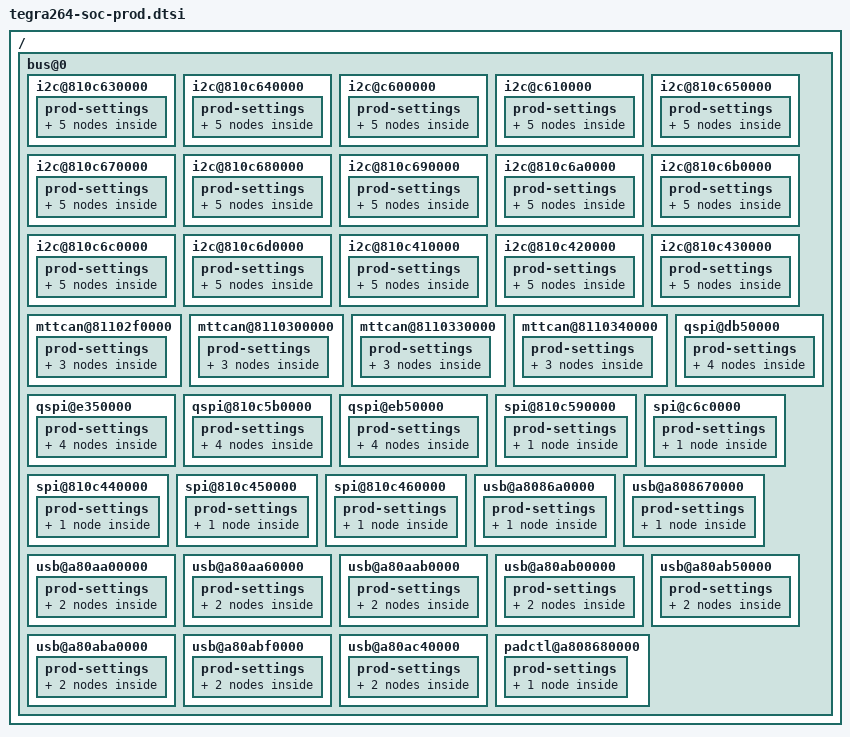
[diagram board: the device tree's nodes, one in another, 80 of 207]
/*
* tegra264-soc-prod.dtsi: soc specific Prod configuration.
* Generation date: 2025-03-05 16:42
* PLEASE DO NOT EDIT THIS FILE MANUALLY
* This file is autogenerated using the script gen_prod_dtsi.py V2.4 in $TOP/tools/golden-regs/host_tools_python3/auto_gen_tools 
* NOTE: Do not use file as is. Copy the relevant section to existing                 file in tree.
* NOTE: FIXME nodes indicate nodes corresponding to Golden Register                 were not found in input DTB.
*       Please check if DTB has the nodes enabled and register address                 in GR DB is valid.
*/

/ {


	bus@0{
		i2c@810c630000 { /* I2C0 */
			prod-settings {
				#prod-cells = <4>;
				prod {
					prod = <

						0 0x000000d4 0x000000ff 0x00000000              //I2C_I2C_INTERFACE_TIMING_2_0
						0 0x000000d8 0x000000ff 0x00000000              //I2C_I2C_HS_INTERFACE_TIMING_2_0
						0 0x000000dc 0x0000ffff 0x00000001              //I2C_I2C_MSTR_DATA_CAPTURE_TIMING_0
						0 0x000000e0 0x0000ffff 0x00000002>;            //I2C_I2C_SLV_DATA_CAPTURE_TIMING_0
				};
				prod_c_fm {
					prod = <
						0 0x0000006c 0xffff0000 0x00150000              //I2C_I2C_CLK_DIVISOR_REGISTER_0
						0 0x00000094 0x0000ffff 0x00000202              //I2C_I2C_INTERFACE_TIMING_0_0
						0 0x00000098 0xffffffff 0x02020202              //I2C_I2C_INTERFACE_TIMING_1_0
						0 0x000000e8 0x000000ff 0x00000040>;            //I2C_I2C_FAIRNESS_ARBITRATION_0
				};
				prod_c_fmplus {
					prod = <
						0 0x0000006c 0xffff0000 0x00080000              //I2C_I2C_CLK_DIVISOR_REGISTER_0
						0 0x00000094 0x0000ffff 0x00000202              //I2C_I2C_INTERFACE_TIMING_0_0
						0 0x00000098 0xffffffff 0x02020202              //I2C_I2C_INTERFACE_TIMING_1_0
						0 0x000000e8 0x000000ff 0x00000040>;            //I2C_I2C_FAIRNESS_ARBITRATION_0
				};
				prod_c_hs {
					prod = <
						0 0x0000006c 0xffffffff 0x001d0002              //I2C_I2C_CLK_DIVISOR_REGISTER_0
						0 0x00000094 0x0000ffff 0x00000202              //I2C_I2C_INTERFACE_TIMING_0_0
						0 0x00000098 0xffffffff 0x02020202              //I2C_I2C_INTERFACE_TIMING_1_0
						0 0x0000009c 0x0000ffff 0x00000102              //I2C_I2C_HS_INTERFACE_TIMING_0_0
						0 0x000000a0 0x00ffffff 0x00040404              //I2C_I2C_HS_INTERFACE_TIMING_1_0
						0 0x000000e8 0x000000ff 0x00000040>;            //I2C_I2C_FAIRNESS_ARBITRATION_0
				};
				prod_c_sm {
					prod = <
						0 0x0000006c 0xffff0000 0x001d0000              //I2C_I2C_CLK_DIVISOR_REGISTER_0
						0 0x00000094 0x0000ffff 0x00000708              //I2C_I2C_INTERFACE_TIMING_0_0
						0 0x00000098 0xffffffff 0x08080808              //I2C_I2C_INTERFACE_TIMING_1_0
						0 0x000000e8 0x000000ff 0x00000040>;            //I2C_I2C_FAIRNESS_ARBITRATION_0
				};
			};
		};

		i2c@810c640000 { /* I2C1 */
			prod-settings {
				#prod-cells = <4>;
				prod {
					prod = <

						0 0x000000d4 0x000000ff 0x00000000              //I2C_I2C_INTERFACE_TIMING_2_0
						0 0x000000d8 0x000000ff 0x00000000              //I2C_I2C_HS_INTERFACE_TIMING_2_0
						0 0x000000dc 0x0000ffff 0x00000001              //I2C_I2C_MSTR_DATA_CAPTURE_TIMING_0
						0 0x000000e0 0x0000ffff 0x00000002>;            //I2C_I2C_SLV_DATA_CAPTURE_TIMING_0
				};
				prod_c_fm {
					prod = <
						0 0x0000006c 0xffff0000 0x00150000              //I2C_I2C_CLK_DIVISOR_REGISTER_0
						0 0x00000094 0x0000ffff 0x00000202              //I2C_I2C_INTERFACE_TIMING_0_0
						0 0x00000098 0xffffffff 0x02020202              //I2C_I2C_INTERFACE_TIMING_1_0
						0 0x000000e8 0x000000ff 0x00000040>;            //I2C_I2C_FAIRNESS_ARBITRATION_0
				};
				prod_c_fmplus {
					prod = <
						0 0x0000006c 0xffff0000 0x00080000              //I2C_I2C_CLK_DIVISOR_REGISTER_0
						0 0x00000094 0x0000ffff 0x00000202              //I2C_I2C_INTERFACE_TIMING_0_0
						0 0x00000098 0xffffffff 0x02020202              //I2C_I2C_INTERFACE_TIMING_1_0
						0 0x000000e8 0x000000ff 0x00000040>;            //I2C_I2C_FAIRNESS_ARBITRATION_0
				};
				prod_c_hs {
					prod = <
						0 0x0000006c 0xffffffff 0x001d0002              //I2C_I2C_CLK_DIVISOR_REGISTER_0
						0 0x00000094 0x0000ffff 0x00000202              //I2C_I2C_INTERFACE_TIMING_0_0
						0 0x00000098 0xffffffff 0x02020202              //I2C_I2C_INTERFACE_TIMING_1_0
						0 0x0000009c 0x0000ffff 0x00000102              //I2C_I2C_HS_INTERFACE_TIMING_0_0
						0 0x000000a0 0x00ffffff 0x00040404              //I2C_I2C_HS_INTERFACE_TIMING_1_0
						0 0x000000e8 0x000000ff 0x00000040>;            //I2C_I2C_FAIRNESS_ARBITRATION_0
				};
				prod_c_sm {
					prod = <
						0 0x0000006c 0xffff0000 0x001d0000              //I2C_I2C_CLK_DIVISOR_REGISTER_0
						0 0x00000094 0x0000ffff 0x00000708              //I2C_I2C_INTERFACE_TIMING_0_0
						0 0x00000098 0xffffffff 0x08080808              //I2C_I2C_INTERFACE_TIMING_1_0
						0 0x000000e8 0x000000ff 0x00000040>;            //I2C_I2C_FAIRNESS_ARBITRATION_0
				};
			};
		};

		i2c@c600000 { /* I2C2 */
			prod-settings {
				#prod-cells = <4>;
				prod {
					prod = <

						0 0x000000d4 0x000000ff 0x00000000              //I2C_I2C_INTERFACE_TIMING_2_0
						0 0x000000d8 0x000000ff 0x00000000              //I2C_I2C_HS_INTERFACE_TIMING_2_0
						0 0x000000dc 0x0000ffff 0x00000001              //I2C_I2C_MSTR_DATA_CAPTURE_TIMING_0
						0 0x000000e0 0x0000ffff 0x00000002>;            //I2C_I2C_SLV_DATA_CAPTURE_TIMING_0
				};
				prod_c_fm {
					prod = <
						0 0x0000006c 0xffff0000 0x00180000              //I2C_I2C_CLK_DIVISOR_REGISTER_0
						0 0x00000094 0x0000ffff 0x00000202              //I2C_I2C_INTERFACE_TIMING_0_0
						0 0x00000098 0xffffffff 0x02020202              //I2C_I2C_INTERFACE_TIMING_1_0
						0 0x000000e8 0x000000ff 0x00000040>;            //I2C_I2C_FAIRNESS_ARBITRATION_0
				};
				prod_c_fmplus {
					prod = <
						0 0x0000006c 0xffff0000 0x00090000              //I2C_I2C_CLK_DIVISOR_REGISTER_0
						0 0x00000094 0x0000ffff 0x00000202              //I2C_I2C_INTERFACE_TIMING_0_0
						0 0x00000098 0xffffffff 0x02020202              //I2C_I2C_INTERFACE_TIMING_1_0
						0 0x000000e8 0x000000ff 0x00000040>;            //I2C_I2C_FAIRNESS_ARBITRATION_0
				};
				prod_c_hs {
					prod = <
						0 0x0000006c 0xffffffff 0x00180002              //I2C_I2C_CLK_DIVISOR_REGISTER_0
						0 0x00000094 0x0000ffff 0x00000202              //I2C_I2C_INTERFACE_TIMING_0_0
						0 0x00000098 0xffffffff 0x02020202              //I2C_I2C_INTERFACE_TIMING_1_0
						0 0x000000a0 0x00ffffff 0x00090909              //I2C_I2C_HS_INTERFACE_TIMING_1_0
						0 0x000000e8 0x000000ff 0x00000040>;            //I2C_I2C_FAIRNESS_ARBITRATION_0
				};
				prod_c_sm {
					prod = <
						0 0x0000006c 0xffff0000 0x00230000              //I2C_I2C_CLK_DIVISOR_REGISTER_0
						0 0x00000094 0x0000ffff 0x00000708              //I2C_I2C_INTERFACE_TIMING_0_0
						0 0x00000098 0xffffffff 0x08080808              //I2C_I2C_INTERFACE_TIMING_1_0
						0 0x000000e8 0x000000ff 0x00000040>;            //I2C_I2C_FAIRNESS_ARBITRATION_0
				};
			};
		};

		i2c@c610000 { /* I2C3 */
			prod-settings {
				#prod-cells = <4>;
				prod {
					prod = <

						0 0x000000d4 0x000000ff 0x00000000              //I2C_I2C_INTERFACE_TIMING_2_0
						0 0x000000d8 0x000000ff 0x00000000              //I2C_I2C_HS_INTERFACE_TIMING_2_0
						0 0x000000dc 0x0000ffff 0x00000001              //I2C_I2C_MSTR_DATA_CAPTURE_TIMING_0
						0 0x000000e0 0x0000ffff 0x00000002>;            //I2C_I2C_SLV_DATA_CAPTURE_TIMING_0
				};
				prod_c_fm {
					prod = <
						0 0x0000006c 0xffff0000 0x00180000              //I2C_I2C_CLK_DIVISOR_REGISTER_0
						0 0x00000094 0x0000ffff 0x00000202              //I2C_I2C_INTERFACE_TIMING_0_0
						0 0x00000098 0xffffffff 0x02020202              //I2C_I2C_INTERFACE_TIMING_1_0
						0 0x000000e8 0x000000ff 0x00000040>;            //I2C_I2C_FAIRNESS_ARBITRATION_0
				};
				prod_c_fmplus {
					prod = <
						0 0x0000006c 0xffff0000 0x00090000              //I2C_I2C_CLK_DIVISOR_REGISTER_0
						0 0x00000094 0x0000ffff 0x00000202              //I2C_I2C_INTERFACE_TIMING_0_0
						0 0x00000098 0xffffffff 0x02020202              //I2C_I2C_INTERFACE_TIMING_1_0
						0 0x000000e8 0x000000ff 0x00000040>;            //I2C_I2C_FAIRNESS_ARBITRATION_0
				};
				prod_c_hs {
					prod = <
						0 0x0000006c 0xffffffff 0x00180002              //I2C_I2C_CLK_DIVISOR_REGISTER_0
						0 0x00000094 0x0000ffff 0x00000202              //I2C_I2C_INTERFACE_TIMING_0_0
						0 0x00000098 0xffffffff 0x02020202              //I2C_I2C_INTERFACE_TIMING_1_0
						0 0x000000a0 0x00ffffff 0x00090909              //I2C_I2C_HS_INTERFACE_TIMING_1_0
						0 0x000000e8 0x000000ff 0x00000040>;            //I2C_I2C_FAIRNESS_ARBITRATION_0
				};
				prod_c_sm {
					prod = <
						0 0x0000006c 0xffff0000 0x00230000              //I2C_I2C_CLK_DIVISOR_REGISTER_0
						0 0x00000094 0x0000ffff 0x00000708              //I2C_I2C_INTERFACE_TIMING_0_0
						0 0x00000098 0xffffffff 0x08080808              //I2C_I2C_INTERFACE_TIMING_1_0
						0 0x000000e8 0x000000ff 0x00000040>;            //I2C_I2C_FAIRNESS_ARBITRATION_0
				};
			};
		};

		i2c@810c650000 { /* I2C4 */
			prod-settings {
				#prod-cells = <4>;
				prod {
					prod = <

						0 0x000000d4 0x000000ff 0x00000000              //I2C_I2C_INTERFACE_TIMING_2_0
						0 0x000000d8 0x000000ff 0x00000000              //I2C_I2C_HS_INTERFACE_TIMING_2_0
						0 0x000000dc 0x0000ffff 0x00000001              //I2C_I2C_MSTR_DATA_CAPTURE_TIMING_0
						0 0x000000e0 0x0000ffff 0x00000002>;            //I2C_I2C_SLV_DATA_CAPTURE_TIMING_0
				};
				prod_c_fm {
					prod = <
						0 0x0000006c 0xffff0000 0x00150000              //I2C_I2C_CLK_DIVISOR_REGISTER_0
						0 0x00000094 0x0000ffff 0x00000202              //I2C_I2C_INTERFACE_TIMING_0_0
						0 0x00000098 0xffffffff 0x02020202              //I2C_I2C_INTERFACE_TIMING_1_0
						0 0x000000e8 0x000000ff 0x00000040>;            //I2C_I2C_FAIRNESS_ARBITRATION_0
				};
				prod_c_fmplus {
					prod = <
						0 0x0000006c 0xffff0000 0x00080000              //I2C_I2C_CLK_DIVISOR_REGISTER_0
						0 0x00000094 0x0000ffff 0x00000202              //I2C_I2C_INTERFACE_TIMING_0_0
						0 0x00000098 0xffffffff 0x02020202              //I2C_I2C_INTERFACE_TIMING_1_0
						0 0x000000e8 0x000000ff 0x00000040>;            //I2C_I2C_FAIRNESS_ARBITRATION_0
				};
				prod_c_hs {
					prod = <
						0 0x0000006c 0xffffffff 0x001d0002              //I2C_I2C_CLK_DIVISOR_REGISTER_0
						0 0x00000094 0x0000ffff 0x00000202              //I2C_I2C_INTERFACE_TIMING_0_0
						0 0x00000098 0xffffffff 0x02020202              //I2C_I2C_INTERFACE_TIMING_1_0
						0 0x0000009c 0x0000ffff 0x00000102              //I2C_I2C_HS_INTERFACE_TIMING_0_0
						0 0x000000a0 0x00ffffff 0x00040404              //I2C_I2C_HS_INTERFACE_TIMING_1_0
						0 0x000000e8 0x000000ff 0x00000040>;            //I2C_I2C_FAIRNESS_ARBITRATION_0
				};
				prod_c_sm {
					prod = <
						0 0x0000006c 0xffff0000 0x001d0000              //I2C_I2C_CLK_DIVISOR_REGISTER_0
						0 0x00000094 0x0000ffff 0x00000708              //I2C_I2C_INTERFACE_TIMING_0_0
						0 0x00000098 0xffffffff 0x08080808              //I2C_I2C_INTERFACE_TIMING_1_0
						0 0x000000e8 0x000000ff 0x00000040>;            //I2C_I2C_FAIRNESS_ARBITRATION_0
				};
			};
		};



		i2c@810c670000 { /* I2C6 */
			prod-settings {
				#prod-cells = <4>;
				prod {
					prod = <

						0 0x000000d4 0x000000ff 0x00000000              //I2C_I2C_INTERFACE_TIMING_2_0
						0 0x000000d8 0x000000ff 0x00000000              //I2C_I2C_HS_INTERFACE_TIMING_2_0
						0 0x000000dc 0x0000ffff 0x00000001              //I2C_I2C_MSTR_DATA_CAPTURE_TIMING_0
						0 0x000000e0 0x0000ffff 0x00000002>;            //I2C_I2C_SLV_DATA_CAPTURE_TIMING_0
				};
				prod_c_fm {
					prod = <
						0 0x0000006c 0xffff0000 0x00150000              //I2C_I2C_CLK_DIVISOR_REGISTER_0
						0 0x00000094 0x0000ffff 0x00000202              //I2C_I2C_INTERFACE_TIMING_0_0
						0 0x00000098 0xffffffff 0x02020202              //I2C_I2C_INTERFACE_TIMING_1_0
						0 0x000000e8 0x000000ff 0x00000040>;            //I2C_I2C_FAIRNESS_ARBITRATION_0
				};
				prod_c_fmplus {
					prod = <
						0 0x0000006c 0xffff0000 0x00080000              //I2C_I2C_CLK_DIVISOR_REGISTER_0
						0 0x00000094 0x0000ffff 0x00000202              //I2C_I2C_INTERFACE_TIMING_0_0
						0 0x00000098 0xffffffff 0x02020202              //I2C_I2C_INTERFACE_TIMING_1_0
						0 0x000000e8 0x000000ff 0x00000040>;            //I2C_I2C_FAIRNESS_ARBITRATION_0
				};
				prod_c_hs {
					prod = <
						0 0x0000006c 0xffffffff 0x001d0002              //I2C_I2C_CLK_DIVISOR_REGISTER_0
						0 0x00000094 0x0000ffff 0x00000202              //I2C_I2C_INTERFACE_TIMING_0_0
						0 0x00000098 0xffffffff 0x02020202              //I2C_I2C_INTERFACE_TIMING_1_0
						0 0x0000009c 0x0000ffff 0x00000102              //I2C_I2C_HS_INTERFACE_TIMING_0_0
						0 0x000000a0 0x00ffffff 0x00040404              //I2C_I2C_HS_INTERFACE_TIMING_1_0
						0 0x000000e8 0x000000ff 0x00000040>;            //I2C_I2C_FAIRNESS_ARBITRATION_0
				};
				prod_c_sm {
					prod = <
						0 0x0000006c 0xffff0000 0x001d0000              //I2C_I2C_CLK_DIVISOR_REGISTER_0
						0 0x00000094 0x0000ffff 0x00000708              //I2C_I2C_INTERFACE_TIMING_0_0
						0 0x00000098 0xffffffff 0x08080808              //I2C_I2C_INTERFACE_TIMING_1_0
						0 0x000000e8 0x000000ff 0x00000040>;            //I2C_I2C_FAIRNESS_ARBITRATION_0
				};
			};
		};

		i2c@810c680000 { /* I2C7 */
			prod-settings {
				#prod-cells = <4>;
				prod {
					prod = <

						0 0x000000d4 0x000000ff 0x00000000              //I2C_I2C_INTERFACE_TIMING_2_0
						0 0x000000d8 0x000000ff 0x00000000              //I2C_I2C_HS_INTERFACE_TIMING_2_0
						0 0x000000dc 0x0000ffff 0x00000001              //I2C_I2C_MSTR_DATA_CAPTURE_TIMING_0
						0 0x000000e0 0x0000ffff 0x00000002>;            //I2C_I2C_SLV_DATA_CAPTURE_TIMING_0
				};
				prod_c_fm {
					prod = <
						0 0x0000006c 0xffff0000 0x00150000              //I2C_I2C_CLK_DIVISOR_REGISTER_0
						0 0x00000094 0x0000ffff 0x00000202              //I2C_I2C_INTERFACE_TIMING_0_0
						0 0x00000098 0xffffffff 0x02020202              //I2C_I2C_INTERFACE_TIMING_1_0
						0 0x000000e8 0x000000ff 0x00000040>;            //I2C_I2C_FAIRNESS_ARBITRATION_0
				};
				prod_c_fmplus {
					prod = <
						0 0x0000006c 0xffff0000 0x00080000              //I2C_I2C_CLK_DIVISOR_REGISTER_0
						0 0x00000094 0x0000ffff 0x00000202              //I2C_I2C_INTERFACE_TIMING_0_0
						0 0x00000098 0xffffffff 0x02020202              //I2C_I2C_INTERFACE_TIMING_1_0
						0 0x000000e8 0x000000ff 0x00000040>;            //I2C_I2C_FAIRNESS_ARBITRATION_0
				};
				prod_c_hs {
					prod = <
						0 0x0000006c 0xffffffff 0x001d0002              //I2C_I2C_CLK_DIVISOR_REGISTER_0
						0 0x00000094 0x0000ffff 0x00000202              //I2C_I2C_INTERFACE_TIMING_0_0
						0 0x00000098 0xffffffff 0x02020202              //I2C_I2C_INTERFACE_TIMING_1_0
						0 0x0000009c 0x0000ffff 0x00000102              //I2C_I2C_HS_INTERFACE_TIMING_0_0
						0 0x000000a0 0x00ffffff 0x00040404              //I2C_I2C_HS_INTERFACE_TIMING_1_0
						0 0x000000e8 0x000000ff 0x00000040>;            //I2C_I2C_FAIRNESS_ARBITRATION_0
				};
				prod_c_sm {
					prod = <
						0 0x0000006c 0xffff0000 0x001d0000              //I2C_I2C_CLK_DIVISOR_REGISTER_0
						0 0x00000094 0x0000ffff 0x00000708              //I2C_I2C_INTERFACE_TIMING_0_0
						0 0x00000098 0xffffffff 0x08080808              //I2C_I2C_INTERFACE_TIMING_1_0
						0 0x000000e8 0x000000ff 0x00000040>;            //I2C_I2C_FAIRNESS_ARBITRATION_0
				};
			};
		};

		i2c@810c690000 { /* I2C8 */
			prod-settings {
				#prod-cells = <4>;
				prod {
					prod = <

						0 0x000000d4 0x000000ff 0x00000000              //I2C_I2C_INTERFACE_TIMING_2_0
						0 0x000000d8 0x000000ff 0x00000000              //I2C_I2C_HS_INTERFACE_TIMING_2_0
						0 0x000000dc 0x0000ffff 0x00000001              //I2C_I2C_MSTR_DATA_CAPTURE_TIMING_0
						0 0x000000e0 0x0000ffff 0x00000002>;            //I2C_I2C_SLV_DATA_CAPTURE_TIMING_0
				};
				prod_c_fm {
					prod = <
						0 0x0000006c 0xffff0000 0x00150000              //I2C_I2C_CLK_DIVISOR_REGISTER_0
						0 0x00000094 0x0000ffff 0x00000202              //I2C_I2C_INTERFACE_TIMING_0_0
						0 0x00000098 0xffffffff 0x02020202              //I2C_I2C_INTERFACE_TIMING_1_0
						0 0x000000e8 0x000000ff 0x00000040>;            //I2C_I2C_FAIRNESS_ARBITRATION_0
				};
				prod_c_fmplus {
					prod = <
						0 0x0000006c 0xffff0000 0x00080000              //I2C_I2C_CLK_DIVISOR_REGISTER_0
						0 0x00000094 0x0000ffff 0x00000202              //I2C_I2C_INTERFACE_TIMING_0_0
						0 0x00000098 0xffffffff 0x02020202              //I2C_I2C_INTERFACE_TIMING_1_0
						0 0x000000e8 0x000000ff 0x00000040>;            //I2C_I2C_FAIRNESS_ARBITRATION_0
				};
				prod_c_hs {
					prod = <
						0 0x0000006c 0xffffffff 0x001d0002              //I2C_I2C_CLK_DIVISOR_REGISTER_0
						0 0x00000094 0x0000ffff 0x00000202              //I2C_I2C_INTERFACE_TIMING_0_0
						0 0x00000098 0xffffffff 0x02020202              //I2C_I2C_INTERFACE_TIMING_1_0
						0 0x0000009c 0x0000ffff 0x00000102              //I2C_I2C_HS_INTERFACE_TIMING_0_0
						0 0x000000a0 0x00ffffff 0x00040404              //I2C_I2C_HS_INTERFACE_TIMING_1_0
						0 0x000000e8 0x000000ff 0x00000040>;            //I2C_I2C_FAIRNESS_ARBITRATION_0
				};
				prod_c_sm {
					prod = <
						0 0x0000006c 0xffff0000 0x001d0000              //I2C_I2C_CLK_DIVISOR_REGISTER_0
						0 0x00000094 0x0000ffff 0x00000708              //I2C_I2C_INTERFACE_TIMING_0_0
						0 0x00000098 0xffffffff 0x08080808              //I2C_I2C_INTERFACE_TIMING_1_0
						0 0x000000e8 0x000000ff 0x00000040>;            //I2C_I2C_FAIRNESS_ARBITRATION_0
				};
			};
		};

		i2c@810c6a0000 { /* I2C9 */
			prod-settings {
				#prod-cells = <4>;
				prod {
					prod = <

						0 0x000000d4 0x000000ff 0x00000000              //I2C_I2C_INTERFACE_TIMING_2_0
						0 0x000000d8 0x000000ff 0x00000000              //I2C_I2C_HS_INTERFACE_TIMING_2_0
						0 0x000000dc 0x0000ffff 0x00000001              //I2C_I2C_MSTR_DATA_CAPTURE_TIMING_0
						0 0x000000e0 0x0000ffff 0x00000002>;            //I2C_I2C_SLV_DATA_CAPTURE_TIMING_0
				};
				prod_c_fm {
					prod = <
						0 0x0000006c 0xffff0000 0x00150000              //I2C_I2C_CLK_DIVISOR_REGISTER_0
						0 0x00000094 0x0000ffff 0x00000202              //I2C_I2C_INTERFACE_TIMING_0_0
						0 0x00000098 0xffffffff 0x02020202              //I2C_I2C_INTERFACE_TIMING_1_0
						0 0x000000e8 0x000000ff 0x00000040>;            //I2C_I2C_FAIRNESS_ARBITRATION_0
				};
				prod_c_fmplus {
					prod = <
						0 0x0000006c 0xffff0000 0x00080000              //I2C_I2C_CLK_DIVISOR_REGISTER_0
						0 0x00000094 0x0000ffff 0x00000202              //I2C_I2C_INTERFACE_TIMING_0_0
						0 0x00000098 0xffffffff 0x02020202              //I2C_I2C_INTERFACE_TIMING_1_0
						0 0x000000e8 0x000000ff 0x00000040>;            //I2C_I2C_FAIRNESS_ARBITRATION_0
				};
				prod_c_hs {
					prod = <
						0 0x0000006c 0xffffffff 0x001d0002              //I2C_I2C_CLK_DIVISOR_REGISTER_0
						0 0x00000094 0x0000ffff 0x00000202              //I2C_I2C_INTERFACE_TIMING_0_0
						0 0x00000098 0xffffffff 0x02020202              //I2C_I2C_INTERFACE_TIMING_1_0
						0 0x0000009c 0x0000ffff 0x00000102              //I2C_I2C_HS_INTERFACE_TIMING_0_0
						0 0x000000a0 0x00ffffff 0x00040404              //I2C_I2C_HS_INTERFACE_TIMING_1_0
						0 0x000000e8 0x000000ff 0x00000040>;            //I2C_I2C_FAIRNESS_ARBITRATION_0
				};
				prod_c_sm {
					prod = <
						0 0x0000006c 0xffff0000 0x001d0000              //I2C_I2C_CLK_DIVISOR_REGISTER_0
						0 0x00000094 0x0000ffff 0x00000708              //I2C_I2C_INTERFACE_TIMING_0_0
						0 0x00000098 0xffffffff 0x08080808              //I2C_I2C_INTERFACE_TIMING_1_0
						0 0x000000e8 0x000000ff 0x00000040>;            //I2C_I2C_FAIRNESS_ARBITRATION_0
				};
			};
		};
		i2c@810c6b0000 { /* I2C10 */
			prod-settings {
				#prod-cells = <4>;
				prod {
					prod = <

						0 0x000000d4 0x000000ff 0x00000000              //I2C_I2C_INTERFACE_TIMING_2_0
						0 0x000000d8 0x000000ff 0x00000000              //I2C_I2C_HS_INTERFACE_TIMING_2_0
						0 0x000000dc 0x0000ffff 0x00000001              //I2C_I2C_MSTR_DATA_CAPTURE_TIMING_0
						0 0x000000e0 0x0000ffff 0x00000002>;            //I2C_I2C_SLV_DATA_CAPTURE_TIMING_0
				};
				prod_c_fm {
					prod = <
						0 0x0000006c 0xffff0000 0x00150000              //I2C_I2C_CLK_DIVISOR_REGISTER_0
						0 0x00000094 0x0000ffff 0x00000202              //I2C_I2C_INTERFACE_TIMING_0_0
						0 0x00000098 0xffffffff 0x02020202              //I2C_I2C_INTERFACE_TIMING_1_0
						0 0x000000e8 0x000000ff 0x00000040>;            //I2C_I2C_FAIRNESS_ARBITRATION_0
				};
				prod_c_fmplus {
					prod = <
						0 0x0000006c 0xffff0000 0x00080000              //I2C_I2C_CLK_DIVISOR_REGISTER_0
						0 0x00000094 0x0000ffff 0x00000202              //I2C_I2C_INTERFACE_TIMING_0_0
						0 0x00000098 0xffffffff 0x02020202              //I2C_I2C_INTERFACE_TIMING_1_0
						0 0x000000e8 0x000000ff 0x00000040>;            //I2C_I2C_FAIRNESS_ARBITRATION_0
				};
				prod_c_hs {
					prod = <
						0 0x0000006c 0xffffffff 0x001d0002              //I2C_I2C_CLK_DIVISOR_REGISTER_0
						0 0x00000094 0x0000ffff 0x00000202              //I2C_I2C_INTERFACE_TIMING_0_0
						0 0x00000098 0xffffffff 0x02020202              //I2C_I2C_INTERFACE_TIMING_1_0
						0 0x0000009c 0x0000ffff 0x00000102              //I2C_I2C_HS_INTERFACE_TIMING_0_0
						0 0x000000a0 0x00ffffff 0x00040404              //I2C_I2C_HS_INTERFACE_TIMING_1_0
						0 0x000000e8 0x000000ff 0x00000040>;            //I2C_I2C_FAIRNESS_ARBITRATION_0
				};
				prod_c_sm {
					prod = <
						0 0x0000006c 0xffff0000 0x001d0000              //I2C_I2C_CLK_DIVISOR_REGISTER_0
						0 0x00000094 0x0000ffff 0x00000708              //I2C_I2C_INTERFACE_TIMING_0_0
						0 0x00000098 0xffffffff 0x08080808              //I2C_I2C_INTERFACE_TIMING_1_0
						0 0x000000e8 0x000000ff 0x00000040>;            //I2C_I2C_FAIRNESS_ARBITRATION_0
				};
			};
		};

		i2c@810c6c0000 { /* I2C11 */
			prod-settings {
				#prod-cells = <4>;
				prod {
					prod = <

						0 0x000000d4 0x000000ff 0x00000000              //I2C_I2C_INTERFACE_TIMING_2_0
						0 0x000000d8 0x000000ff 0x00000000              //I2C_I2C_HS_INTERFACE_TIMING_2_0
						0 0x000000dc 0x0000ffff 0x00000001              //I2C_I2C_MSTR_DATA_CAPTURE_TIMING_0
						0 0x000000e0 0x0000ffff 0x00000002>;            //I2C_I2C_SLV_DATA_CAPTURE_TIMING_0
				};
				prod_c_fm {
					prod = <
						0 0x0000006c 0xffff0000 0x00150000              //I2C_I2C_CLK_DIVISOR_REGISTER_0
						0 0x00000094 0x0000ffff 0x00000202              //I2C_I2C_INTERFACE_TIMING_0_0
						0 0x00000098 0xffffffff 0x02020202              //I2C_I2C_INTERFACE_TIMING_1_0
						0 0x000000e8 0x000000ff 0x00000040>;            //I2C_I2C_FAIRNESS_ARBITRATION_0
				};
				prod_c_fmplus {
					prod = <
						0 0x0000006c 0xffff0000 0x00080000              //I2C_I2C_CLK_DIVISOR_REGISTER_0
						0 0x00000094 0x0000ffff 0x00000202              //I2C_I2C_INTERFACE_TIMING_0_0
						0 0x00000098 0xffffffff 0x02020202              //I2C_I2C_INTERFACE_TIMING_1_0
						0 0x000000e8 0x000000ff 0x00000040>;            //I2C_I2C_FAIRNESS_ARBITRATION_0
				};
				prod_c_hs {
					prod = <
						0 0x0000006c 0xffffffff 0x001d0002              //I2C_I2C_CLK_DIVISOR_REGISTER_0
						0 0x00000094 0x0000ffff 0x00000202              //I2C_I2C_INTERFACE_TIMING_0_0
						0 0x00000098 0xffffffff 0x02020202              //I2C_I2C_INTERFACE_TIMING_1_0
						0 0x0000009c 0x0000ffff 0x00000102              //I2C_I2C_HS_INTERFACE_TIMING_0_0
						0 0x000000a0 0x00ffffff 0x00040404              //I2C_I2C_HS_INTERFACE_TIMING_1_0
						0 0x000000e8 0x000000ff 0x00000040>;            //I2C_I2C_FAIRNESS_ARBITRATION_0
				};
				prod_c_sm {
					prod = <
						0 0x0000006c 0xffff0000 0x001d0000              //I2C_I2C_CLK_DIVISOR_REGISTER_0
						0 0x00000094 0x0000ffff 0x00000708              //I2C_I2C_INTERFACE_TIMING_0_0
						0 0x00000098 0xffffffff 0x08080808              //I2C_I2C_INTERFACE_TIMING_1_0
						0 0x000000e8 0x000000ff 0x00000040>;            //I2C_I2C_FAIRNESS_ARBITRATION_0
				};
			};
		};

		i2c@810c6d0000 { /* I2C12 */
			prod-settings {
				#prod-cells = <4>;
				prod {
					prod = <

						0 0x000000d4 0x000000ff 0x00000000              //I2C_I2C_INTERFACE_TIMING_2_0
						0 0x000000d8 0x000000ff 0x00000000              //I2C_I2C_HS_INTERFACE_TIMING_2_0
						0 0x000000dc 0x0000ffff 0x00000001              //I2C_I2C_MSTR_DATA_CAPTURE_TIMING_0
						0 0x000000e0 0x0000ffff 0x00000002>;            //I2C_I2C_SLV_DATA_CAPTURE_TIMING_0
				};
				prod_c_fm {
					prod = <
						0 0x0000006c 0xffff0000 0x00150000              //I2C_I2C_CLK_DIVISOR_REGISTER_0
						0 0x00000094 0x0000ffff 0x00000202              //I2C_I2C_INTERFACE_TIMING_0_0
						0 0x00000098 0xffffffff 0x02020202              //I2C_I2C_INTERFACE_TIMING_1_0
						0 0x000000e8 0x000000ff 0x00000040>;            //I2C_I2C_FAIRNESS_ARBITRATION_0
				};
				prod_c_fmplus {
					prod = <
						0 0x0000006c 0xffff0000 0x00080000              //I2C_I2C_CLK_DIVISOR_REGISTER_0
						0 0x00000094 0x0000ffff 0x00000202              //I2C_I2C_INTERFACE_TIMING_0_0
						0 0x00000098 0xffffffff 0x02020202              //I2C_I2C_INTERFACE_TIMING_1_0
						0 0x000000e8 0x000000ff 0x00000040>;            //I2C_I2C_FAIRNESS_ARBITRATION_0
				};
				prod_c_hs {
					prod = <
						0 0x0000006c 0xffffffff 0x001d0002              //I2C_I2C_CLK_DIVISOR_REGISTER_0
						0 0x00000094 0x0000ffff 0x00000202              //I2C_I2C_INTERFACE_TIMING_0_0
						0 0x00000098 0xffffffff 0x02020202              //I2C_I2C_INTERFACE_TIMING_1_0
						0 0x0000009c 0x0000ffff 0x00000102              //I2C_I2C_HS_INTERFACE_TIMING_0_0
						0 0x000000a0 0x00ffffff 0x00040404              //I2C_I2C_HS_INTERFACE_TIMING_1_0
						0 0x000000e8 0x000000ff 0x00000040>;            //I2C_I2C_FAIRNESS_ARBITRATION_0
				};
				prod_c_sm {
					prod = <
						0 0x0000006c 0xffff0000 0x001d0000              //I2C_I2C_CLK_DIVISOR_REGISTER_0
						0 0x00000094 0x0000ffff 0x00000708              //I2C_I2C_INTERFACE_TIMING_0_0
						0 0x00000098 0xffffffff 0x08080808              //I2C_I2C_INTERFACE_TIMING_1_0
						0 0x000000e8 0x000000ff 0x00000040>;            //I2C_I2C_FAIRNESS_ARBITRATION_0
				};
			};
		};

		i2c@810c410000 { /* I2C14 */
			prod-settings {
				#prod-cells = <4>;
				prod {
					prod = <

						0 0x000000d4 0x000000ff 0x00000000              //I2C_I2C_INTERFACE_TIMING_2_0
						0 0x000000d8 0x000000ff 0x00000000              //I2C_I2C_HS_INTERFACE_TIMING_2_0
						0 0x000000dc 0x0000ffff 0x00000001              //I2C_I2C_MSTR_DATA_CAPTURE_TIMING_0
						0 0x000000e0 0x0000ffff 0x00000002>;            //I2C_I2C_SLV_DATA_CAPTURE_TIMING_0
				};
				prod_c_fm {
					prod = <
						0 0x0000006c 0xffff0000 0x00150000              //I2C_I2C_CLK_DIVISOR_REGISTER_0
						0 0x00000094 0x0000ffff 0x00000202              //I2C_I2C_INTERFACE_TIMING_0_0
						0 0x00000098 0xffffffff 0x02020202              //I2C_I2C_INTERFACE_TIMING_1_0
						0 0x000000e8 0x000000ff 0x00000040>;            //I2C_I2C_FAIRNESS_ARBITRATION_0
				};
				prod_c_fmplus {
					prod = <
						0 0x0000006c 0xffff0000 0x00080000              //I2C_I2C_CLK_DIVISOR_REGISTER_0
						0 0x00000094 0x0000ffff 0x00000202              //I2C_I2C_INTERFACE_TIMING_0_0
						0 0x00000098 0xffffffff 0x02020202              //I2C_I2C_INTERFACE_TIMING_1_0
						0 0x000000e8 0x000000ff 0x00000040>;            //I2C_I2C_FAIRNESS_ARBITRATION_0
				};
				prod_c_hs {
					prod = <
						0 0x0000006c 0xffffffff 0x001d0002              //I2C_I2C_CLK_DIVISOR_REGISTER_0
						0 0x00000094 0x0000ffff 0x00000202              //I2C_I2C_INTERFACE_TIMING_0_0
						0 0x00000098 0xffffffff 0x02020202              //I2C_I2C_INTERFACE_TIMING_1_0
						0 0x0000009c 0x0000ffff 0x00000102              //I2C_I2C_HS_INTERFACE_TIMING_0_0
						0 0x000000a0 0x00ffffff 0x00040404              //I2C_I2C_HS_INTERFACE_TIMING_1_0
						0 0x000000e8 0x000000ff 0x00000040>;            //I2C_I2C_FAIRNESS_ARBITRATION_0
				};
				prod_c_sm {
					prod = <
						0 0x0000006c 0xffff0000 0x001d0000              //I2C_I2C_CLK_DIVISOR_REGISTER_0
						0 0x00000094 0x0000ffff 0x00000708              //I2C_I2C_INTERFACE_TIMING_0_0
						0 0x00000098 0xffffffff 0x08080808              //I2C_I2C_INTERFACE_TIMING_1_0
						0 0x000000e8 0x000000ff 0x00000040>;            //I2C_I2C_FAIRNESS_ARBITRATION_0
				};
			};
		};

		i2c@810c420000 { /* I2C15 */
			prod-settings {
				#prod-cells = <4>;
				prod {
					prod = <

						0 0x000000d4 0x000000ff 0x00000000              //I2C_I2C_INTERFACE_TIMING_2_0
						0 0x000000d8 0x000000ff 0x00000000              //I2C_I2C_HS_INTERFACE_TIMING_2_0
						0 0x000000dc 0x0000ffff 0x00000001              //I2C_I2C_MSTR_DATA_CAPTURE_TIMING_0
						0 0x000000e0 0x0000ffff 0x00000002>;            //I2C_I2C_SLV_DATA_CAPTURE_TIMING_0
				};
				prod_c_fm {
					prod = <
						0 0x0000006c 0xffff0000 0x00150000              //I2C_I2C_CLK_DIVISOR_REGISTER_0
						0 0x00000094 0x0000ffff 0x00000202              //I2C_I2C_INTERFACE_TIMING_0_0
						0 0x00000098 0xffffffff 0x02020202              //I2C_I2C_INTERFACE_TIMING_1_0
						0 0x000000e8 0x000000ff 0x00000040>;            //I2C_I2C_FAIRNESS_ARBITRATION_0
				};
				prod_c_fmplus {
					prod = <
						0 0x0000006c 0xffff0000 0x00080000              //I2C_I2C_CLK_DIVISOR_REGISTER_0
						0 0x00000094 0x0000ffff 0x00000202              //I2C_I2C_INTERFACE_TIMING_0_0
						0 0x00000098 0xffffffff 0x02020202              //I2C_I2C_INTERFACE_TIMING_1_0
						0 0x000000e8 0x000000ff 0x00000040>;            //I2C_I2C_FAIRNESS_ARBITRATION_0
				};
				prod_c_hs {
					prod = <
						0 0x0000006c 0xffffffff 0x001d0002              //I2C_I2C_CLK_DIVISOR_REGISTER_0
						0 0x00000094 0x0000ffff 0x00000202              //I2C_I2C_INTERFACE_TIMING_0_0
						0 0x00000098 0xffffffff 0x02020202              //I2C_I2C_INTERFACE_TIMING_1_0
						0 0x0000009c 0x0000ffff 0x00000102              //I2C_I2C_HS_INTERFACE_TIMING_0_0
						0 0x000000a0 0x00ffffff 0x00040404              //I2C_I2C_HS_INTERFACE_TIMING_1_0
						0 0x000000e8 0x000000ff 0x00000040>;            //I2C_I2C_FAIRNESS_ARBITRATION_0
				};
				prod_c_sm {
					prod = <
						0 0x0000006c 0xffff0000 0x001d0000              //I2C_I2C_CLK_DIVISOR_REGISTER_0
						0 0x00000094 0x0000ffff 0x00000708              //I2C_I2C_INTERFACE_TIMING_0_0
						0 0x00000098 0xffffffff 0x08080808              //I2C_I2C_INTERFACE_TIMING_1_0
						0 0x000000e8 0x000000ff 0x00000040>;            //I2C_I2C_FAIRNESS_ARBITRATION_0
				};
			};
		};

		i2c@810c430000 { /* I2C16 */
			prod-settings {
				#prod-cells = <4>;
				prod {
					prod = <

						0 0x000000d4 0x000000ff 0x00000000              //I2C_I2C_INTERFACE_TIMING_2_0
						0 0x000000d8 0x000000ff 0x00000000              //I2C_I2C_HS_INTERFACE_TIMING_2_0
						0 0x000000dc 0x0000ffff 0x00000001              //I2C_I2C_MSTR_DATA_CAPTURE_TIMING_0
						0 0x000000e0 0x0000ffff 0x00000002>;            //I2C_I2C_SLV_DATA_CAPTURE_TIMING_0
				};
				prod_c_fm {
					prod = <
						0 0x0000006c 0xffff0000 0x00150000              //I2C_I2C_CLK_DIVISOR_REGISTER_0
						0 0x00000094 0x0000ffff 0x00000202              //I2C_I2C_INTERFACE_TIMING_0_0
						0 0x00000098 0xffffffff 0x02020202              //I2C_I2C_INTERFACE_TIMING_1_0
						0 0x000000e8 0x000000ff 0x00000040>;            //I2C_I2C_FAIRNESS_ARBITRATION_0
				};
				prod_c_fmplus {
					prod = <
						0 0x0000006c 0xffff0000 0x00080000              //I2C_I2C_CLK_DIVISOR_REGISTER_0
						0 0x00000094 0x0000ffff 0x00000202              //I2C_I2C_INTERFACE_TIMING_0_0
						0 0x00000098 0xffffffff 0x02020202              //I2C_I2C_INTERFACE_TIMING_1_0
						0 0x000000e8 0x000000ff 0x00000040>;            //I2C_I2C_FAIRNESS_ARBITRATION_0
				};
				prod_c_hs {
					prod = <
						0 0x0000006c 0xffffffff 0x001d0002              //I2C_I2C_CLK_DIVISOR_REGISTER_0
						0 0x00000094 0x0000ffff 0x00000202              //I2C_I2C_INTERFACE_TIMING_0_0
						0 0x00000098 0xffffffff 0x02020202              //I2C_I2C_INTERFACE_TIMING_1_0
						0 0x0000009c 0x0000ffff 0x00000102              //I2C_I2C_HS_INTERFACE_TIMING_0_0
						0 0x000000a0 0x00ffffff 0x00040404              //I2C_I2C_HS_INTERFACE_TIMING_1_0
						0 0x000000e8 0x000000ff 0x00000040>;            //I2C_I2C_FAIRNESS_ARBITRATION_0
				};
				prod_c_sm {
					prod = <
						0 0x0000006c 0xffff0000 0x001d0000              //I2C_I2C_CLK_DIVISOR_REGISTER_0
						0 0x00000094 0x0000ffff 0x00000708              //I2C_I2C_INTERFACE_TIMING_0_0
						0 0x00000098 0xffffffff 0x08080808              //I2C_I2C_INTERFACE_TIMING_1_0
						0 0x000000e8 0x000000ff 0x00000040>;            //I2C_I2C_FAIRNESS_ARBITRATION_0
				};
			};
		};

		mttcan@81102f0000 {
			prod-settings {
				#prod-cells = <4>;
				prod_c_can_2m_1m {
					prod = <
						0 0x0000000c 0x00800000 0x00000000              //M_TTCAN_CORE_DBTP_0
						0 0x00000048 0x00007f00 0x00000000>;            //M_TTCAN_CORE_TDCR_0
				};
				prod_c_can_5m {
					prod = <
						0 0x0000000c 0x00800000 0x00800000              //M_TTCAN_CORE_DBTP_0
						0 0x00000048 0x00007f00 0x00000600>;            //M_TTCAN_CORE_TDCR_0
				};
				prod_c_can_8m {
					prod = <
						0 0x0000000c 0x00800000 0x00800000              //M_TTCAN_CORE_DBTP_0
						0 0x00000048 0x00007f00 0x00000400>;            //M_TTCAN_CORE_TDCR_0
				};
			};
		};

		mttcan@8110300000 {
			prod-settings {
				#prod-cells = <4>;
				prod_c_can_2m_1m {
					prod = <
						0 0x0000000c 0x00800000 0x00000000              //M_TTCAN_CORE_DBTP_0
						0 0x00000048 0x00007f00 0x00000000>;            //M_TTCAN_CORE_TDCR_0
				};
				prod_c_can_5m {
					prod = <
						0 0x0000000c 0x00800000 0x00800000              //M_TTCAN_CORE_DBTP_0
						0 0x00000048 0x00007f00 0x00000600>;            //M_TTCAN_CORE_TDCR_0
				};
				prod_c_can_8m {
					prod = <
						0 0x0000000c 0x00800000 0x00800000              //M_TTCAN_CORE_DBTP_0
						0 0x00000048 0x00007f00 0x00000400>;            //M_TTCAN_CORE_TDCR_0
				};
			};
		};

		mttcan@8110330000 {
			prod-settings {
				#prod-cells = <4>;
				prod_c_can_2m_1m {
					prod = <
						0 0x0000000c 0x00800000 0x00000000              //M_TTCAN_CORE_DBTP_0
						0 0x00000048 0x00007f00 0x00000000>;            //M_TTCAN_CORE_TDCR_0
				};
				prod_c_can_5m {
					prod = <
						0 0x0000000c 0x00800000 0x00800000              //M_TTCAN_CORE_DBTP_0
						0 0x00000048 0x00007f00 0x00000600>;            //M_TTCAN_CORE_TDCR_0
				};
				prod_c_can_8m {
					prod = <
						0 0x0000000c 0x00800000 0x00800000              //M_TTCAN_CORE_DBTP_0
						0 0x00000048 0x00007f00 0x00000400>;            //M_TTCAN_CORE_TDCR_0
				};
			};
		};

		mttcan@8110340000 {
			prod-settings {
				#prod-cells = <4>;
				prod_c_can_2m_1m {
					prod = <
						0 0x0000000c 0x00800000 0x00000000              //M_TTCAN_CORE_DBTP_0
						0 0x00000048 0x00007f00 0x00000000>;            //M_TTCAN_CORE_TDCR_0
				};
				prod_c_can_5m {
					prod = <
						0 0x0000000c 0x00800000 0x00800000              //M_TTCAN_CORE_DBTP_0
						0 0x00000048 0x00007f00 0x00000600>;            //M_TTCAN_CORE_TDCR_0
				};
				prod_c_can_8m {
					prod = <
						0 0x0000000c 0x00800000 0x00800000              //M_TTCAN_CORE_DBTP_0
						0 0x00000048 0x00007f00 0x00000400>;            //M_TTCAN_CORE_TDCR_0
				};
			};
		};

		qspi@db50000 {
			prod-settings {
				#prod-cells = <4>;
				prod_c_nonsecure {
					prod = <
						0 0x0000f000 0x0000003f 0x00000012>;            //QSPI_SECURE_AXI_CTL_0
				};
				prod_c_nopwrsave {
					prod = <
						0 0x00000194 0x80000000 0x80000000              //QSPI_MISC_0
						0 0x000001ec 0x00000002 0x00000000              //QSPI_QSPI_COMP_CONTROL_0
						0 0x000001fc 0x00000002 0x00000000>;            //QSPI_IO_TRIM_CNTRL_0
				};
				prod_c_pwrsave {
					prod = <
						0 0x00000194 0x80000000 0x00000000              //QSPI_MISC_0
						0 0x000001ec 0x00000002 0x00000002              //QSPI_QSPI_COMP_CONTROL_0
						0 0x000001fc 0x00000002 0x00000002>;            //QSPI_IO_TRIM_CNTRL_0
				};
				prod_c_secure {
					prod = <
						0 0x0000f000 0x0000003f 0x00000000>;            //QSPI_SECURE_AXI_CTL_0
				};
			};
		};
		
		qspi@e350000 {
			prod-settings {
				#prod-cells = <4>;
				prod_c_nonsecure {
					prod = <
						0 0x0000f000 0x0000003f 0x00000012>;            //QSPI_SECURE_AXI_CTL_0
				};
				prod_c_nopwrsave {
					prod = <
						0 0x00000194 0x80000000 0x80000000              //QSPI_MISC_0
						0 0x000001ec 0x00000002 0x00000000              //QSPI_QSPI_COMP_CONTROL_0
						0 0x000001fc 0x00000002 0x00000000>;            //QSPI_IO_TRIM_CNTRL_0
				};
				prod_c_pwrsave {
					prod = <
						0 0x00000194 0x80000000 0x00000000              //QSPI_MISC_0
						0 0x000001ec 0x00000002 0x00000002              //QSPI_QSPI_COMP_CONTROL_0
						0 0x000001fc 0x00000002 0x00000002>;            //QSPI_IO_TRIM_CNTRL_0
				};
				prod_c_secure {
					prod = <
						0 0x0000f000 0x0000003f 0x00000000>;            //QSPI_SECURE_AXI_CTL_0
				};
			};
		};
		
		qspi@810c5b0000 {
			prod-settings {
				#prod-cells = <4>;
				prod_c_nonsecure {
					prod = <
						0 0x0000f000 0x0000003f 0x00000012>;            //QSPI_SECURE_AXI_CTL_0
				};
				prod_c_nopwrsave {
					prod = <
						0 0x00000194 0x80000000 0x80000000              //QSPI_MISC_0
						0 0x000001ec 0x00000002 0x00000000              //QSPI_QSPI_COMP_CONTROL_0
						0 0x000001fc 0x00000002 0x00000000>;            //QSPI_IO_TRIM_CNTRL_0
				};
				prod_c_pwrsave {
					prod = <
						0 0x00000194 0x80000000 0x00000000              //QSPI_MISC_0
						0 0x000001ec 0x00000002 0x00000002              //QSPI_QSPI_COMP_CONTROL_0
						0 0x000001fc 0x00000002 0x00000002>;            //QSPI_IO_TRIM_CNTRL_0
				};
				prod_c_secure {
					prod = <
						0 0x0000f000 0x0000003f 0x00000000>;            //QSPI_SECURE_AXI_CTL_0
				};
			};
		};
		
		qspi@eb50000 {
			prod-settings {
				#prod-cells = <4>;
				prod_c_nonsecure {
					prod = <
						0 0x0000f000 0x0000003f 0x00000012>;            //QSPI_SECURE_AXI_CTL_0
				};
				prod_c_nopwrsave {
					prod = <
						0 0x00000194 0x80000000 0x80000000              //QSPI_MISC_0
						0 0x000001ec 0x00000002 0x00000000              //QSPI_QSPI_COMP_CONTROL_0
						0 0x000001fc 0x00000002 0x00000000>;            //QSPI_IO_TRIM_CNTRL_0
				};
				prod_c_pwrsave {
					prod = <
						0 0x00000194 0x80000000 0x00000000              //QSPI_MISC_0
						0 0x000001ec 0x00000002 0x00000002              //QSPI_QSPI_COMP_CONTROL_0
						0 0x000001fc 0x00000002 0x00000002>;            //QSPI_IO_TRIM_CNTRL_0
				};
				prod_c_secure {
					prod = <
						0 0x0000f000 0x0000003f 0x00000000>;            //QSPI_SECURE_AXI_CTL_0
				};
			};
		};
		
		spi@810c590000 {
			prod-settings {
				#prod-cells = <4>;
				prod {
					prod = <
						0 0x00000194 0x80000000 0x00000000>;            //SPI_MISC_0
				};
			};
		};
		
		spi@c6c0000 {
			prod-settings {
				#prod-cells = <4>;
				prod {
					prod = <
						0 0x00000194 0x80000000 0x00000000>;            //SPI_MISC_0
				};
			};
		};
		
		spi@810c440000 {
			prod-settings {
				#prod-cells = <4>;
				prod {
					prod = <
						0 0x00000194 0x80000000 0x00000000>;            //SPI_MISC_0
				};
			};
		};
	
		spi@810c450000 {
			prod-settings {
				#prod-cells = <4>;
				prod {
					prod = <
						0 0x00000194 0x80000000 0x00000000>;            //SPI_MISC_0
				};
			};
		};
	
		spi@810c460000 {
			prod-settings {
				#prod-cells = <4>;
				prod {
					prod = <
						0 0x00000194 0x80000000 0x00000000>;            //SPI_MISC_0
				};
			};
		};
		
		usb@a8086a0000 {
			prod-settings {
				#prod-cells = <4>;
				prod {
					prod = <
						0 0x00000004 0x0000000f 0x00000001>;            //XUSB_AO_USB_DEBOUNCE_DEL_0
				};
			};
		};
	
		usb@a808670000 {
			prod-settings {
				#prod-cells = <4>;
				prod {
					prod = <
						0 0x00000030 0x80000012 0x80000012              //T_XUSB_DEV_XHCI_CTRL_0
						0 0x00000134 0x3fffffff 0x00002c88              //T_XUSB_DEV_XHCI_HSFSPI_COUNT13_0
						0 0x00000840 0x00000100 0x00000000              //T_XUSB_DEV_XHCI_BLCG_0
						0 0x00000858 0xffffffff 0x0000f000>;            //T_XUSB_DEV_XHCI_CFG_DEV_SSPI_XFER_0
				};
			};
		};
		
		usb@a80aa00000 {
			prod-settings {
				#prod-cells = <4>;
				prod {
					prod = <
						0 0x000000d8 0x00000001 0x00000000              //T_XUSB_MSI_QUEUE_0
						0 0x0000400c 0x07ff0000 0x01600000              //T_XUSB_CFG_SSPX_CORE_CTRL_0
						0 0x00004090 0x000000ff 0x0000003b              //T_XUSB_CFG_SSPX_CORE_CNT32_0
						0 0x00004118 0x00000fff 0x00000013              //T_XUSB_CFG_SSPX_CORE_CNT63_0
						0 0x0000416c 0x00000001 0x00000001              //T_XUSB_CFG_SSPX_CORE_ASYNC_0
						0 0x00004500 0x00000fff 0x00000357              //T_XUSB_CFG_SSPX_P2U_CORE_UPHYCTL_TX2_0
						0 0x00004504 0x00000fff 0x00000348              //T_XUSB_CFG_SSPX_P2U_CORE_UPHYCTL_TX3_0
						0 0x0000450c 0x00000fff 0x00000348              //T_XUSB_CFG_SSPX_P2U_CORE_UPHYCTL_RX2_0
						0 0x00004514 0xfff00000 0x34800000              //T_XUSB_CFG_SSPX_P2U_CORE_UPHYCTL_RX4_0
						0 0x00004528 0x0000fff0 0x00003480              //T_XUSB_CFG_SSPX_P2U_CORE_UPHYCTL_TX4_0
						0 0x00004554 0x00000002 0x00000002>;            //T_XUSB_CFG_SSPX_P2U_CORE_UPHYCTL_CAL_CTL_0
				};
				prod_c_xusb_cfg_aru_c11pagesel0_bit0 {
					prod = <
						0 0x000007e0 0xffffffff 0x00004000>;            //T_XUSB_CFG_RB_BKDRVTIOSOFF_0
				};
			};
		};
		
		usb@a80aa60000 {
			prod-settings {
				#prod-cells = <4>;
				prod {
					prod = <
						0 0x000000d8 0x00000001 0x00000000              //T_XUSB_MSI_QUEUE_0
						0 0x0000400c 0x07ff0000 0x01600000              //T_XUSB_CFG_SSPX_CORE_CTRL_0
						0 0x00004090 0x000000ff 0x0000003b              //T_XUSB_CFG_SSPX_CORE_CNT32_0
						0 0x00004118 0x00000fff 0x00000013              //T_XUSB_CFG_SSPX_CORE_CNT63_0
						0 0x0000416c 0x00000001 0x00000001              //T_XUSB_CFG_SSPX_CORE_ASYNC_0
						0 0x00004500 0x00000fff 0x00000357              //T_XUSB_CFG_SSPX_P2U_CORE_UPHYCTL_TX2_0
						0 0x00004504 0x00000fff 0x00000348              //T_XUSB_CFG_SSPX_P2U_CORE_UPHYCTL_TX3_0
						0 0x0000450c 0x00000fff 0x00000348              //T_XUSB_CFG_SSPX_P2U_CORE_UPHYCTL_RX2_0
						0 0x00004514 0xfff00000 0x34800000              //T_XUSB_CFG_SSPX_P2U_CORE_UPHYCTL_RX4_0
						0 0x00004528 0x0000fff0 0x00003480              //T_XUSB_CFG_SSPX_P2U_CORE_UPHYCTL_TX4_0
						0 0x00004554 0x00000002 0x00000002>;            //T_XUSB_CFG_SSPX_P2U_CORE_UPHYCTL_CAL_CTL_0
				};
				prod_c_xusb_cfg_aru_c11pagesel0_bit0 {
					prod = <
						0 0x000007e0 0xffffffff 0x00004000>;            //T_XUSB_CFG_RB_BKDRVTIOSOFF_0
				};
			};
		};
		
		usb@a80aab0000 {
			prod-settings {
				#prod-cells = <4>;
				prod {
					prod = <
						0 0x000000d8 0x00000001 0x00000000              //T_XUSB_MSI_QUEUE_0
						0 0x0000400c 0x07ff0000 0x01600000              //T_XUSB_CFG_SSPX_CORE_CTRL_0
						0 0x00004090 0x000000ff 0x0000003b              //T_XUSB_CFG_SSPX_CORE_CNT32_0
						0 0x00004118 0x00000fff 0x00000013              //T_XUSB_CFG_SSPX_CORE_CNT63_0
						0 0x0000416c 0x00000001 0x00000001              //T_XUSB_CFG_SSPX_CORE_ASYNC_0
						0 0x00004500 0x00000fff 0x00000357              //T_XUSB_CFG_SSPX_P2U_CORE_UPHYCTL_TX2_0
						0 0x00004504 0x00000fff 0x00000348              //T_XUSB_CFG_SSPX_P2U_CORE_UPHYCTL_TX3_0
						0 0x0000450c 0x00000fff 0x00000348              //T_XUSB_CFG_SSPX_P2U_CORE_UPHYCTL_RX2_0
						0 0x00004514 0xfff00000 0x34800000              //T_XUSB_CFG_SSPX_P2U_CORE_UPHYCTL_RX4_0
						0 0x00004528 0x0000fff0 0x00003480              //T_XUSB_CFG_SSPX_P2U_CORE_UPHYCTL_TX4_0
						0 0x00004554 0x00000002 0x00000002>;            //T_XUSB_CFG_SSPX_P2U_CORE_UPHYCTL_CAL_CTL_0
				};
				prod_c_xusb_cfg_aru_c11pagesel0_bit0 {
					prod = <
						0 0x000007e0 0xffffffff 0x00004000>;            //T_XUSB_CFG_RB_BKDRVTIOSOFF_0
				};
			};
		};
		
		usb@a80ab00000 {
			prod-settings {
				#prod-cells = <4>;
				prod {
					prod = <
						0 0x000000d8 0x00000001 0x00000000              //T_XUSB_MSI_QUEUE_0
						0 0x0000400c 0x07ff0000 0x01600000              //T_XUSB_CFG_SSPX_CORE_CTRL_0
						0 0x00004090 0x000000ff 0x0000003b              //T_XUSB_CFG_SSPX_CORE_CNT32_0
						0 0x00004118 0x00000fff 0x00000013              //T_XUSB_CFG_SSPX_CORE_CNT63_0
						0 0x0000416c 0x00000001 0x00000001              //T_XUSB_CFG_SSPX_CORE_ASYNC_0
						0 0x00004500 0x00000fff 0x00000357              //T_XUSB_CFG_SSPX_P2U_CORE_UPHYCTL_TX2_0
						0 0x00004504 0x00000fff 0x00000348              //T_XUSB_CFG_SSPX_P2U_CORE_UPHYCTL_TX3_0
						0 0x0000450c 0x00000fff 0x00000348              //T_XUSB_CFG_SSPX_P2U_CORE_UPHYCTL_RX2_0
						0 0x00004514 0xfff00000 0x34800000              //T_XUSB_CFG_SSPX_P2U_CORE_UPHYCTL_RX4_0
						0 0x00004528 0x0000fff0 0x00003480              //T_XUSB_CFG_SSPX_P2U_CORE_UPHYCTL_TX4_0
						0 0x00004554 0x00000002 0x00000002>;            //T_XUSB_CFG_SSPX_P2U_CORE_UPHYCTL_CAL_CTL_0
				};
				prod_c_xusb_cfg_aru_c11pagesel0_bit0 {
					prod = <
						0 0x000007e0 0xffffffff 0x00004000>;            //T_XUSB_CFG_RB_BKDRVTIOSOFF_0
				};
			};
		};
		
		usb@a80ab50000 {
			prod-settings {
				#prod-cells = <4>;
				prod {
					prod = <
						0 0x000000d8 0x00000001 0x00000000              //T_XUSB_MSI_QUEUE_0
						0 0x0000400c 0x07ff0000 0x01600000              //T_XUSB_CFG_SSPX_CORE_CTRL_0
						0 0x00004090 0x000000ff 0x0000003b              //T_XUSB_CFG_SSPX_CORE_CNT32_0
						0 0x00004118 0x00000fff 0x00000013              //T_XUSB_CFG_SSPX_CORE_CNT63_0
						0 0x0000416c 0x00000001 0x00000001              //T_XUSB_CFG_SSPX_CORE_ASYNC_0
						0 0x00004500 0x00000fff 0x00000357              //T_XUSB_CFG_SSPX_P2U_CORE_UPHYCTL_TX2_0
						0 0x00004504 0x00000fff 0x00000348              //T_XUSB_CFG_SSPX_P2U_CORE_UPHYCTL_TX3_0
						0 0x0000450c 0x00000fff 0x00000348              //T_XUSB_CFG_SSPX_P2U_CORE_UPHYCTL_RX2_0
						0 0x00004514 0xfff00000 0x34800000              //T_XUSB_CFG_SSPX_P2U_CORE_UPHYCTL_RX4_0
						0 0x00004528 0x0000fff0 0x00003480              //T_XUSB_CFG_SSPX_P2U_CORE_UPHYCTL_TX4_0
						0 0x00004554 0x00000002 0x00000002>;            //T_XUSB_CFG_SSPX_P2U_CORE_UPHYCTL_CAL_CTL_0
				};
				prod_c_xusb_cfg_aru_c11pagesel0_bit0 {
					prod = <
						0 0x000007e0 0xffffffff 0x00004000>;            //T_XUSB_CFG_RB_BKDRVTIOSOFF_0
				};
			};
		};
		
		usb@a80aba0000 {
			prod-settings {
				#prod-cells = <4>;
				prod {
					prod = <
						0 0x000000d8 0x00000001 0x00000000              //T_XUSB_MSI_QUEUE_0
						0 0x0000400c 0x07ff0000 0x01600000              //T_XUSB_CFG_SSPX_CORE_CTRL_0
						0 0x00004090 0x000000ff 0x0000003b              //T_XUSB_CFG_SSPX_CORE_CNT32_0
						0 0x00004118 0x00000fff 0x00000013              //T_XUSB_CFG_SSPX_CORE_CNT63_0
						0 0x0000416c 0x00000001 0x00000001              //T_XUSB_CFG_SSPX_CORE_ASYNC_0
						0 0x00004500 0x00000fff 0x00000357              //T_XUSB_CFG_SSPX_P2U_CORE_UPHYCTL_TX2_0
						0 0x00004504 0x00000fff 0x00000348              //T_XUSB_CFG_SSPX_P2U_CORE_UPHYCTL_TX3_0
						0 0x0000450c 0x00000fff 0x00000348              //T_XUSB_CFG_SSPX_P2U_CORE_UPHYCTL_RX2_0
						0 0x00004514 0xfff00000 0x34800000              //T_XUSB_CFG_SSPX_P2U_CORE_UPHYCTL_RX4_0
						0 0x00004528 0x0000fff0 0x00003480              //T_XUSB_CFG_SSPX_P2U_CORE_UPHYCTL_TX4_0
						0 0x00004554 0x00000002 0x00000002>;            //T_XUSB_CFG_SSPX_P2U_CORE_UPHYCTL_CAL_CTL_0
				};
				prod_c_xusb_cfg_aru_c11pagesel0_bit0 {
					prod = <
						0 0x000007e0 0xffffffff 0x00004000>;            //T_XUSB_CFG_RB_BKDRVTIOSOFF_0
				};
			};
		};
		
		usb@a80abf0000 {
			prod-settings {
				#prod-cells = <4>;
				prod {
					prod = <
						0 0x000000d8 0x00000001 0x00000000              //T_XUSB_MSI_QUEUE_0
						0 0x0000400c 0x07ff0000 0x01600000              //T_XUSB_CFG_SSPX_CORE_CTRL_0
						0 0x00004090 0x000000ff 0x0000003b              //T_XUSB_CFG_SSPX_CORE_CNT32_0
						0 0x00004118 0x00000fff 0x00000013              //T_XUSB_CFG_SSPX_CORE_CNT63_0
						0 0x0000416c 0x00000001 0x00000001              //T_XUSB_CFG_SSPX_CORE_ASYNC_0
						0 0x00004500 0x00000fff 0x00000357              //T_XUSB_CFG_SSPX_P2U_CORE_UPHYCTL_TX2_0
						0 0x00004504 0x00000fff 0x00000348              //T_XUSB_CFG_SSPX_P2U_CORE_UPHYCTL_TX3_0
						0 0x0000450c 0x00000fff 0x00000348              //T_XUSB_CFG_SSPX_P2U_CORE_UPHYCTL_RX2_0
						0 0x00004514 0xfff00000 0x34800000              //T_XUSB_CFG_SSPX_P2U_CORE_UPHYCTL_RX4_0
						0 0x00004528 0x0000fff0 0x00003480              //T_XUSB_CFG_SSPX_P2U_CORE_UPHYCTL_TX4_0
						0 0x00004554 0x00000002 0x00000002>;            //T_XUSB_CFG_SSPX_P2U_CORE_UPHYCTL_CAL_CTL_0
				};
				prod_c_xusb_cfg_aru_c11pagesel0_bit0 {
					prod = <
						0 0x000007e0 0xffffffff 0x00004000>;            //T_XUSB_CFG_RB_BKDRVTIOSOFF_0
				};
			};
		};
		
		usb@a80ac40000 {
			prod-settings {
				#prod-cells = <4>;
				prod {
					prod = <
						0 0x000000d8 0x00000001 0x00000000              //T_XUSB_MSI_QUEUE_0
						0 0x0000400c 0x07ff0000 0x01600000              //T_XUSB_CFG_SSPX_CORE_CTRL_0
						0 0x00004090 0x000000ff 0x0000003b              //T_XUSB_CFG_SSPX_CORE_CNT32_0
						0 0x00004118 0x00000fff 0x00000013              //T_XUSB_CFG_SSPX_CORE_CNT63_0
						0 0x0000416c 0x00000001 0x00000001              //T_XUSB_CFG_SSPX_CORE_ASYNC_0
						0 0x00004500 0x00000fff 0x00000357              //T_XUSB_CFG_SSPX_P2U_CORE_UPHYCTL_TX2_0
						0 0x00004504 0x00000fff 0x00000348              //T_XUSB_CFG_SSPX_P2U_CORE_UPHYCTL_TX3_0
						0 0x0000450c 0x00000fff 0x00000348              //T_XUSB_CFG_SSPX_P2U_CORE_UPHYCTL_RX2_0
						0 0x00004514 0xfff00000 0x34800000              //T_XUSB_CFG_SSPX_P2U_CORE_UPHYCTL_RX4_0
						0 0x00004528 0x0000fff0 0x00003480              //T_XUSB_CFG_SSPX_P2U_CORE_UPHYCTL_TX4_0
						0 0x00004554 0x00000002 0x00000002>;            //T_XUSB_CFG_SSPX_P2U_CORE_UPHYCTL_CAL_CTL_0
				};
				prod_c_xusb_cfg_aru_c11pagesel0_bit0 {
					prod = <
						0 0x000007e0 0xffffffff 0x00004000>;            //T_XUSB_CFG_RB_BKDRVTIOSOFF_0
				};
			};
		};
		
		padctl@a808680000 {
			prod-settings {
				#prod-cells = <4>;
				prod {
					prod = <
						0 0x00000088 0x21fe0000 0x01ba0000              //XUSB_PADCTL_USB2_OTG_PAD0_CTL_0_0
						0 0x00000094 0x03c00000 0x01000000              //XUSB_PADCTL_USB2_OTG_PAD0_CTL_3_0
						0 0x000000c8 0x21fe0000 0x01ba0000              //XUSB_PADCTL_USB2_OTG_PAD1_CTL_0_0
						0 0x000000d4 0x03c00000 0x01000000              //XUSB_PADCTL_USB2_OTG_PAD1_CTL_3_0
						0 0x00000108 0x21fe0000 0x01ba0000              //XUSB_PADCTL_USB2_OTG_PAD2_CTL_0_0
						0 0x00000114 0x03c00000 0x01000000              //XUSB_PADCTL_USB2_OTG_PAD2_CTL_3_0
						0 0x00000148 0x21fe0000 0x01ba0000              //XUSB_PADCTL_USB2_OTG_PAD3_CTL_0_0
						0 0x00000154 0x03c00000 0x01000000              //XUSB_PADCTL_USB2_OTG_PAD3_CTL_3_0
						0 0x00000288 0x03fff000 0x0051e000>;            //XUSB_PADCTL_USB2_BIAS_PAD_CTL_1_0
				};
			};
		};
	};
};
